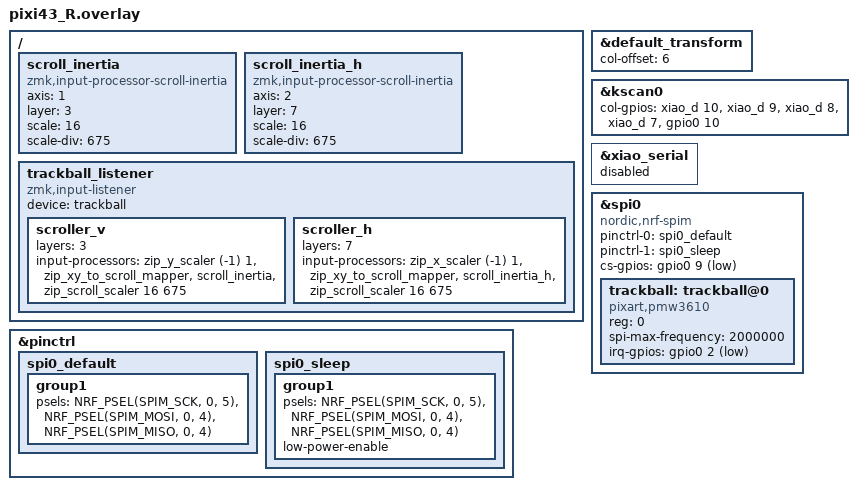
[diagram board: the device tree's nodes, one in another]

#include "pixi43.dtsi"
#include <input/processors.dtsi>
#include <dt-bindings/zmk/modifiers.h>
#include <dt-bindings/zmk/input_transform.h>

&default_transform {
    col-offset = <6>;
};

&kscan0 {
    col-gpios = <&xiao_d 10 GPIO_ACTIVE_HIGH>,
                <&xiao_d 9 GPIO_ACTIVE_HIGH>,
                <&xiao_d 8 GPIO_ACTIVE_HIGH>,
                <&xiao_d 7 GPIO_ACTIVE_HIGH>,
                <&gpio0 10 GPIO_ACTIVE_HIGH>;
};

/ {
    /* Layer 3: Vertical inertia scroll */
    scroll_inertia: scroll_inertia {
        compatible = "zmk,input-processor-scroll-inertia";
        #input-processor-cells = <0>;
        axis = <1>;
        layer = <3>;
        scale = <16>;
        scale-div = <675>;
    };

    /* Layer 7: Horizontal inertia scroll */
    scroll_inertia_h: scroll_inertia_h {
        compatible = "zmk,input-processor-scroll-inertia";
        #input-processor-cells = <0>;
        axis = <2>;
        layer = <7>;
        scale = <16>;
        scale-div = <675>;
    };

    trackball_listener: trackball_listener {
        status = "okay";
        compatible = "zmk,input-listener";
        device = <&trackball>;

        scroller_v {
            layers = <3>;
            input-processors = <
                &zip_y_scaler (-1) 1
                &zip_xy_to_scroll_mapper
                &scroll_inertia
                &zip_scroll_scaler 16 675
            >;
        };

        scroller_h {
            layers = <7>;
            input-processors = <
                &zip_x_scaler (-1) 1
                &zip_xy_to_scroll_mapper
                &scroll_inertia_h
                &zip_scroll_scaler 16 675
            >;
        };
    };
};

&pinctrl {
    spi0_default: spi0_default {
        group1 {
            psels = <NRF_PSEL(SPIM_SCK, 0, 5)>,
                    <NRF_PSEL(SPIM_MOSI, 0, 4)>,
                    <NRF_PSEL(SPIM_MISO, 0, 4)>;
        };
    };

    spi0_sleep: spi0_sleep {
        group1 {
            psels = <NRF_PSEL(SPIM_SCK, 0, 5)>,
                    <NRF_PSEL(SPIM_MOSI, 0, 4)>,
                    <NRF_PSEL(SPIM_MISO, 0, 4)>;
            low-power-enable;
        };
    };
};

&xiao_serial {
    status = "disabled";
};

&spi0 {
    status = "okay";
    compatible = "nordic,nrf-spim";
    pinctrl-0 = <&spi0_default>;
    pinctrl-1 = <&spi0_sleep>;
    pinctrl-names = "default", "sleep";
    cs-gpios = <&gpio0 9 GPIO_ACTIVE_LOW>;

    trackball: trackball@0 {
        status = "okay";
        compatible = "pixart,pmw3610";
        reg = <0>;
        spi-max-frequency = <2000000>;
        irq-gpios = <&gpio0 2 (GPIO_ACTIVE_LOW | GPIO_PULL_UP)>;
    };
};
